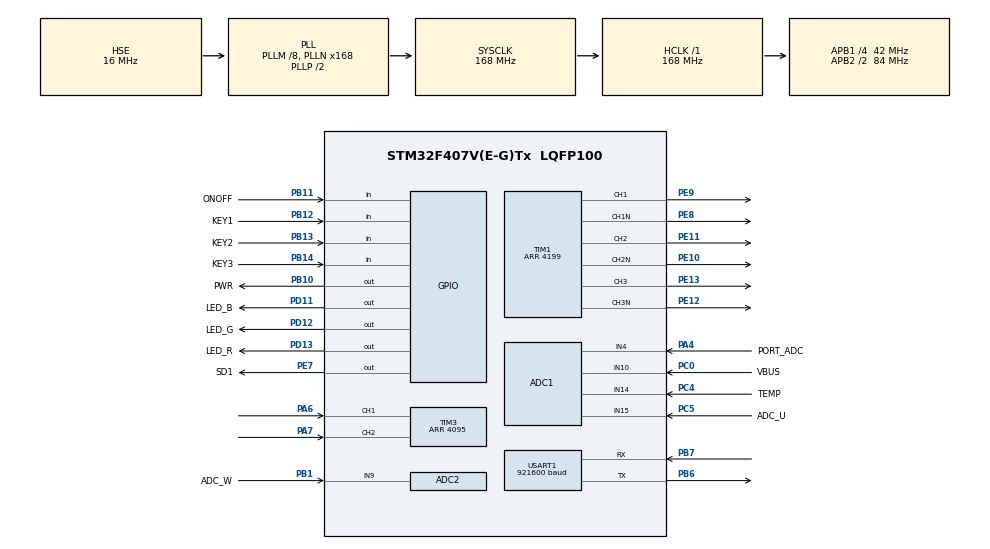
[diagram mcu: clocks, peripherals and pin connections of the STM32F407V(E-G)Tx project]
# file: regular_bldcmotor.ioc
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ADC1.Channel-0\#ChannelRegularConversion=ADC_CHANNEL_10
ADC1.Channel-1\#ChannelRegularConversion=ADC_CHANNEL_14
ADC1.Channel-2\#ChannelRegularConversion=ADC_CHANNEL_4
ADC1.Channel-5\#ChannelInjectedConversion=ADC_CHANNEL_15
ADC1.ContinuousConvMode=DISABLE
ADC1.DMAContinuousRequests=DISABLE
ADC1.EOCSelection=ADC_EOC_SEQ_CONV
ADC1.ExternalTrigInjecConv=ADC_EXTERNALTRIGINJECCONV_T1_TRGO
ADC1.InjNumberOfConversion=1
ADC1.InjectedOffset-5\#ChannelInjectedConversion=0
ADC1.InjectedRank-5\#ChannelInjectedConversion=1
ADC1.Mode=ADC_DUALMODE_INJECSIMULT
ADC1.NbrOfConversion=3
ADC1.NbrOfConversionFlag=1
ADC1.Rank-0\#ChannelRegularConversion=1
ADC1.Rank-1\#ChannelRegularConversion=2
ADC1.Rank-2\#ChannelRegularConversion=3
ADC1.SamplingTime-0\#ChannelRegularConversion=ADC_SAMPLETIME_144CYCLES
ADC1.SamplingTime-1\#ChannelRegularConversion=ADC_SAMPLETIME_144CYCLES
ADC1.SamplingTime-2\#ChannelRegularConversion=ADC_SAMPLETIME_144CYCLES
ADC1.SamplingTime-5\#ChannelInjectedConversion=ADC_SAMPLETIME_15CYCLES
ADC1.ScanConvMode=ENABLE
ADC1.master=1
ADC2.Channel-1\#ChannelRegularConversion=ADC_CHANNEL_9
ADC2.Channel-2\#ChannelInjectedConversion=ADC_CHANNEL_9
ADC2.InjNumberOfConversion=1
ADC2.InjectedOffset-2\#ChannelInjectedConversion=0
ADC2.InjectedRank-2\#ChannelInjectedConversion=1
ADC2.Mode=ADC_DUALMODE_INJECSIMULT
ADC2.NbrOfConversion=1
ADC2.NbrOfConversionFlag=1
ADC2.Rank-1\#ChannelRegularConversion=1
ADC2.SamplingTime-1\#ChannelRegularConversion=ADC_SAMPLETIME_3CYCLES
ADC2.SamplingTime-2\#ChannelInjectedConversion=ADC_SAMPLETIME_15CYCLES
Dma.ADC1.0.Direction=DMA_PERIPH_TO_MEMORY
Dma.ADC1.0.FIFOMode=DMA_FIFOMODE_DISABLE
Dma.ADC1.0.Instance=DMA2_Stream0
Dma.ADC1.0.MemDataAlignment=DMA_MDATAALIGN_HALFWORD
Dma.ADC1.0.MemInc=DMA_MINC_ENABLE
Dma.ADC1.0.Mode=DMA_NORMAL
Dma.ADC1.0.PeriphDataAlignment=DMA_PDATAALIGN_HALFWORD
Dma.ADC1.0.PeriphInc=DMA_PINC_DISABLE
Dma.ADC1.0.Priority=DMA_PRIORITY_HIGH
Dma.Request0=ADC1
Dma.Request1=USART1_RX
Dma.Request2=USART1_TX
Dma.USART1_RX.1.Direction=DMA_PERIPH_TO_MEMORY
Dma.USART1_RX.1.FIFOMode=DMA_FIFOMODE_DISABLE
Dma.USART1_RX.1.Instance=DMA2_Stream2
Dma.USART1_RX.1.MemDataAlignment=DMA_MDATAALIGN_BYTE
Dma.USART1_RX.1.MemInc=DMA_MINC_ENABLE
Dma.USART1_RX.1.Mode=DMA_NORMAL
Dma.USART1_RX.1.PeriphDataAlignment=DMA_PDATAALIGN_BYTE
Dma.USART1_RX.1.PeriphInc=DMA_PINC_DISABLE
Dma.USART1_RX.1.Priority=DMA_PRIORITY_LOW
Dma.USART1_TX.2.Direction=DMA_MEMORY_TO_PERIPH
Dma.USART1_TX.2.FIFOMode=DMA_FIFOMODE_DISABLE
Dma.USART1_TX.2.Instance=DMA2_Stream7
Dma.USART1_TX.2.MemDataAlignment=DMA_MDATAALIGN_BYTE
Dma.USART1_TX.2.MemInc=DMA_MINC_ENABLE
Dma.USART1_TX.2.Mode=DMA_NORMAL
Dma.USART1_TX.2.PeriphDataAlignment=DMA_PDATAALIGN_BYTE
Dma.USART1_TX.2.PeriphInc=DMA_PINC_DISABLE
Dma.USART1_TX.2.Priority=DMA_PRIORITY_LOW
Mcu.Family=STM32F4
Mcu.Name=STM32F407V(E-G)Tx
Mcu.Package=LQFP100
NVIC.ADC_IRQn=true\:0\:0\:false\:false\:true\:true\:true\:true
NVIC.DMA2_Stream0_IRQn=true\:2\:0\:true\:false\:true\:true\:true\:true
NVIC.DMA2_Stream2_IRQn=true\:2\:0\:true\:false\:true\:true\:true\:true
NVIC.DMA2_Stream7_IRQn=true\:2\:0\:true\:false\:true\:true\:true\:true
NVIC.PriorityGroup=NVIC_PRIORITYGROUP_4
NVIC.TIM1_UP_TIM10_IRQn=true\:0\:0\:false\:false\:true\:true\:true\:true
NVIC.TIM4_IRQn=true\:2\:0\:true\:false\:true\:true\:true\:true
NVIC.USART1_IRQn=true\:2\:0\:true\:false\:true\:true\:true\:true
PA13.Mode=Serial_Wire
PA13.Signal=SYS_JTMS-SWDIO
PA14.Mode=Serial_Wire
PA14.Signal=SYS_JTCK-SWCLK
PA4.GPIO_Label=PORT_ADC
PA4.Signal=ADCx_IN4
PA6.Signal=S_TIM3_CH1
PA7.Signal=S_TIM3_CH2
PB1.GPIO_Label=ADC_W
PB1.Signal=ADCx_IN9
PB10.GPIO_Label=PWR
PB10.PinState=GPIO_PIN_SET
PB10.Signal=GPIO_Output
PB11.GPIO_Label=ONOFF
PB11.GPIO_PuPd=GPIO_PULLUP
PB11.Signal=GPIO_Input
PB12.GPIO_Label=KEY1
PB12.GPIO_PuPd=GPIO_PULLUP
PB12.Signal=GPIO_Input
PB13.GPIO_Label=KEY2
PB13.GPIO_PuPd=GPIO_PULLUP
PB13.Signal=GPIO_Input
PB14.GPIO_Label=KEY3
PB14.GPIO_PuPd=GPIO_PULLUP
PB14.Signal=GPIO_Input
PB6.Mode=Asynchronous
PB6.Signal=USART1_TX
PB7.Mode=Asynchronous
PB7.Signal=USART1_RX
PC0.GPIO_Label=VBUS
PC0.Signal=ADCx_IN10
PC4.GPIO_Label=TEMP
PC4.Signal=ADCx_IN14
PC5.GPIO_Label=ADC_U
PC5.Signal=ADCx_IN15
PD11.GPIO_Label=LED_B
PD11.PinState=GPIO_PIN_SET
PD11.Signal=GPIO_Output
PD12.GPIO_Label=LED_G
PD12.PinState=GPIO_PIN_SET
PD12.Signal=GPIO_Output
PD13.GPIO_Label=LED_R
PD13.PinState=GPIO_PIN_SET
PD13.Signal=GPIO_Output
PE10.Mode=PWM Generation2 CH2 CH2N
PE10.Signal=TIM1_CH2N
PE11.Signal=S_TIM1_CH2
PE12.Mode=PWM Generation3 CH3 CH3N
PE12.Signal=TIM1_CH3N
PE13.Signal=S_TIM1_CH3
PE7.GPIO_Label=SD1
PE7.GPIO_Speed=GPIO_SPEED_FREQ_VERY_HIGH
PE7.Signal=GPIO_Output
PE8.Mode=PWM Generation1 CH1 CH1N
PE8.Signal=TIM1_CH1N
PE9.Signal=S_TIM1_CH1
PH0-OSC_IN.Mode=HSE-External-Oscillator
PH0-OSC_IN.Signal=RCC_OSC_IN
PH1-OSC_OUT.Mode=HSE-External-Oscillator
PH1-OSC_OUT.Signal=RCC_OSC_OUT
ProjectManager.HeapSize=0x200
ProjectManager.StackSize=0x400
ProjectManager.TargetToolchain=Makefile
RCC.48MHZClocksFreq_Value=84000000
RCC.AHBFreq_Value=168000000
RCC.APB1CLKDivider=RCC_HCLK_DIV4
RCC.APB1Freq_Value=42000000
RCC.APB1TimFreq_Value=84000000
RCC.APB2CLKDivider=RCC_HCLK_DIV2
RCC.APB2Freq_Value=84000000
RCC.APB2TimFreq_Value=168000000
RCC.CortexFreq_Value=168000000
RCC.HCLKFreq_Value=168000000
RCC.HSE_VALUE=16000000
RCC.HSI_VALUE=16000000
RCC.LSE_VALUE=32768
RCC.PLLM=8
RCC.PLLN=168
RCC.PLLSourceVirtual=RCC_PLLSOURCE_HSE
RCC.SYSCLKFreq_VALUE=168000000
RCC.SYSCLKSource=RCC_SYSCLKSOURCE_PLLCLK
RCC.VCOOutputFreq_Value=336000000
SH.ADCx_IN10.0=ADC1_IN10,IN10
SH.ADCx_IN14.0=ADC1_IN14,IN14
SH.ADCx_IN15.0=ADC1_IN15,IN15
SH.ADCx_IN4.0=ADC1_IN4,IN4
SH.ADCx_IN9.0=ADC2_IN9,IN9
SH.S_TIM1_CH1.0=TIM1_CH1,PWM Generation1 CH1 CH1N
SH.S_TIM1_CH2.0=TIM1_CH2,PWM Generation2 CH2 CH2N
SH.S_TIM1_CH3.0=TIM1_CH3,PWM Generation3 CH3 CH3N
SH.S_TIM3_CH1.0=TIM3_CH1,Encoder_Interface
SH.S_TIM3_CH2.0=TIM3_CH2,Encoder_Interface
TIM1.AutoReloadPreload=TIM_AUTORELOAD_PRELOAD_ENABLE
TIM1.AutomaticOutput=TIM_AUTOMATICOUTPUT_ENABLE
TIM1.Channel-PWM\ Generation1\ CH1\ CH1N=TIM_CHANNEL_1
TIM1.Channel-PWM\ Generation2\ CH2\ CH2N=TIM_CHANNEL_2
TIM1.Channel-PWM\ Generation3\ CH3\ CH3N=TIM_CHANNEL_3
TIM1.Channel-PWM\ Generation4\ No\ Output=TIM_CHANNEL_4
TIM1.CounterMode=TIM_COUNTERMODE_CENTERALIGNED1
TIM1.DeadTime=100
TIM1.OCMode_PWM-PWM\ Generation1\ CH1\ CH1N=TIM_OCMODE_PWM2
TIM1.OCMode_PWM-PWM\ Generation2\ CH2\ CH2N=TIM_OCMODE_PWM2
TIM1.OCMode_PWM-PWM\ Generation3\ CH3\ CH3N=TIM_OCMODE_PWM2
TIM1.OCMode_PWM-PWM\ Generation4\ No\ Output=TIM_OCMODE_PWM2
TIM1.Period=4199
TIM1.Pulse-PWM\ Generation4\ No\ Output=4115
TIM1.TIM_MasterOutputTrigger=TIM_TRGO_OC4REF
TIM3.EncoderMode=TIM_ENCODERMODE_TI12
TIM3.IC1Filter=7
TIM3.IC2Filter=7
TIM3.IC2Polarity=TIM_ICPOLARITY_RISING
TIM3.Period=4095
TIM4.Period=999
TIM4.Prescaler=84-1
USART1.BaudRate=921600
USART1.VirtualMode=VM_ASYNC
VP_TIM1_VS_ClockSourceINT.Mode=Internal
VP_TIM1_VS_no_output4.Mode=PWM Generation4 No Output
VP_TIM4_VS_ClockSourceINT.Mode=Internal
board=custom

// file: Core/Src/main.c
/* USER CODE BEGIN Header */
/**
  ******************************************************************************
  * @file           : main.c
  * @brief          : Main program body
  ******************************************************************************
  * @attention
  *
  * Copyright (c) 2026 STMicroelectronics.
  * All rights reserved.
  *
  * This software is licensed under terms that can be found in the LICENSE file
  * in the root directory of this software component.
  * If no LICENSE file comes with this software, it is provided AS-IS.
  *
  ******************************************************************************
  */
/* USER CODE END Header */
#include "main.h"
#include "adc.h"
#include "dma.h"
#include "tim.h"
#include "usart.h"
#include "gpio.h"

/* USER CODE BEGIN Includes */
#include "task.h"
#include "motor_ctrl.h"
#include "motor_para.h"
/* USER CODE END Includes */

void SystemClock_Config(void);

int main(void)
{

  /* MCU Configuration--------------------------------------------------------*/

  /* Reset of all peripherals, Initializes the Flash interface and the Systick. */
  HAL_Init();

  /* Configure the system clock */
  SystemClock_Config();

  /* Initialize all configured peripherals */
  MX_GPIO_Init();
  MX_DMA_Init();
  MX_TIM4_Init();
  MX_USART1_UART_Init();
  MX_ADC1_Init();
  MX_TIM3_Init();
  MX_TIM1_Init();
  MX_ADC2_Init();
  /* USER CODE BEGIN 2 */
   task_init();
  /* USER CODE END 2 */

  /* Infinite loop */
  while (1)
  {

    /* USER CODE BEGIN 3 */
    task_loop();
  }
  /* USER CODE END 3 */
}

void SystemClock_Config(void)
{
  RCC_OscInitTypeDef RCC_OscInitStruct = {0};
  RCC_ClkInitTypeDef RCC_ClkInitStruct = {0};

  /** Configure the main internal regulator output voltage
  */
  __HAL_RCC_PWR_CLK_ENABLE();
  __HAL_PWR_VOLTAGESCALING_CONFIG(PWR_REGULATOR_VOLTAGE_SCALE1);

  /** Initializes the RCC Oscillators according to the specified parameters
  * in the RCC_OscInitTypeDef structure.
  */
  RCC_OscInitStruct.OscillatorType = RCC_OSCILLATORTYPE_HSE;
  RCC_OscInitStruct.HSEState = RCC_HSE_ON;
  RCC_OscInitStruct.PLL.PLLState = RCC_PLL_ON;
  RCC_OscInitStruct.PLL.PLLSource = RCC_PLLSOURCE_HSE;
  RCC_OscInitStruct.PLL.PLLM = 8;
  RCC_OscInitStruct.PLL.PLLN = 168;
  RCC_OscInitStruct.PLL.PLLP = RCC_PLLP_DIV2;
  RCC_OscInitStruct.PLL.PLLQ = 4;
  if (HAL_RCC_OscConfig(&RCC_OscInitStruct) != HAL_OK)
  {
    Error_Handler();
  }

  /** Initializes the CPU, AHB and APB buses clocks
  */
  RCC_ClkInitStruct.ClockType = RCC_CLOCKTYPE_HCLK|RCC_CLOCKTYPE_SYSCLK
                              |RCC_CLOCKTYPE_PCLK1|RCC_CLOCKTYPE_PCLK2;
  RCC_ClkInitStruct.SYSCLKSource = RCC_SYSCLKSOURCE_PLLCLK;
  RCC_ClkInitStruct.AHBCLKDivider = RCC_SYSCLK_DIV1;
  RCC_ClkInitStruct.APB1CLKDivider = RCC_HCLK_DIV4;
  RCC_ClkInitStruct.APB2CLKDivider = RCC_HCLK_DIV2;

  if (HAL_RCC_ClockConfig(&RCC_ClkInitStruct, FLASH_LATENCY_5) != HAL_OK)
  {
    Error_Handler();
  }
}

void Error_Handler(void)
{
  __disable_irq();
  while (1)
  {
  }
}
